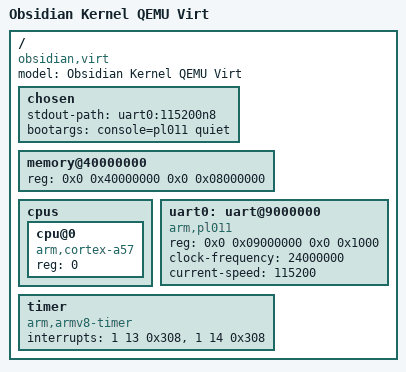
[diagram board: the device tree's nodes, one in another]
/dts-v1/;

/*
 * Obsidian reference device tree for the QEMU virt machine.
 *
 * Build with: dtc -I dts -O dtb -o obsidian-virt.dtb obsidian-virt.dts
 * QEMU also synthesises its own blob at runtime (-machine virt); this
 * file documents the exact hardware contract Obsidian expects and can
 * be passed explicitly via qemu -dtb.
 */

/ {
	model = "Obsidian Kernel QEMU Virt";
	compatible = "obsidian,virt";

	#address-cells = <2>;
	#size-cells = <2>;

	chosen {
		stdout-path = "uart0:115200n8";
		bootargs = "console=pl011 quiet";
	};

	memory@40000000 {
		device_type = "memory";
		reg = <0x0 0x40000000 0x0 0x08000000>;	/* 128 MiB */
	};

	cpus {
		#address-cells = <1>;
		#size-cells = <0>;

		cpu@0 {
			device_type = "cpu";
			compatible = "arm,cortex-a57";
			reg = <0>;
		};
	};

	uart0: uart@9000000 {
		compatible = "arm,pl011", "arm,primecell";
		reg = <0x0 0x09000000 0x0 0x1000>;
		clock-frequency = <24000000>;
		current-speed = <115200>;
	};

	timer {
		compatible = "arm,armv8-timer";
		interrupts = <1 13 0x308>, <1 14 0x308>;
	};
};
